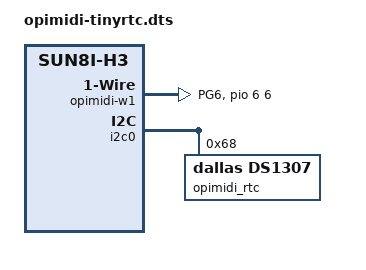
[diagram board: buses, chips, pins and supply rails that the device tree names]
/dts-v1/;
/plugin/;
/ {
	compatible = "xunlong,orangepi-zero", "allwinner,sun8i-h2plus", "allwinner,sun8i-h3";

	/*
	 * TinyRTC module with DS1307 RTC  on i2c bust and DS18B20 temperature sensor on a one-wire bus
	 */ 

	fragment0 {
                // UART1, pins are used for 1wire
		target = <&uart1>;
		__overlay__ {
		    status = "disabled";
		};
	};
        fragment1 {
                // i2c-0, with the DS1307 RTC
		target = <&i2c0>;
		__overlay__ {
                    status = "okay";
                    #address-cells = <1>;
                    #size-cells = <0>;
                    opimidi_rtc: ds1307@68 {
                        compatible = "dallas,ds1307";
                        reg = <0x68>;
                    };
                };
        };
        fragment2 {
                // gpio pin for 1-wire
		target = <&pio>;
		__overlay__ {
                    opimidi_w1_pin: opimidi_w1_pin {
			allwinner,pins = "PG6";
			allwinner,function = "gpio_in";
			allwinner,drive = <0>; //<SUN4I_PINCTRL_10_MA>;
			allwinner,pull = <1>; //<SUN4I_PINCTRL_PULL_UP>;	
                    };
                };
        };
	fragment3 {
		target-path = "/";
		__overlay__ {
                    // 1-wire on PG06 for the DS18B20 sensor
		    opimidi-w1 {
			compatible = "w1-gpio";
			gpios = <&pio 6 6 0>; /* PG6 GPIO_ACTIVE_HIGH */
			pinctrl-names = "default";
			pinctrl-0 = <&opimidi_w1_pin>;
		    };
		};
	};
};

// vi: sw=4 sts=4 et
